AUTOSAR XML (schema 4-2-1)
package /ComponentTypes
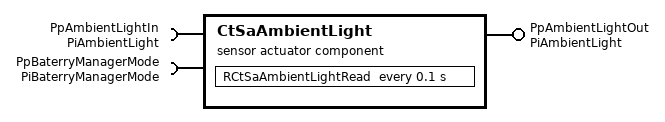
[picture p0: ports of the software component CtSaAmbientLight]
  sensor actuator sw component type CtSaAmbientLight
    provide port PpAmbientLightOut: nonqueued-sender-com-spec{data-element=DeAmbientLight, init-value=0}, provided-interface=PiAmbientLight
    require port PpAmbientLightIn: nonqueued-receiver-com-spec{data-element=DeAmbientLight, filter=data-filter-type=ALWAYS, init-value=0}, required-interface=PiAmbientLight
    require port PpBaterryManagerMode: mode-switch-receiver-com-spec{enhanced-mode-api=false, supports-asynchronous-mode-switch=false}, required-interface=PiBaterryManagerMode
    behavior CtSaAmbientLight_InternalBehavior
      timing event TMT_RCtSaAmbientLightRead: disabled-mode=PpBaterryManagerMode.Mode.BATTERY_LOW, start-on-event=RCtSaAmbientLightRead, period=0.1
      runnable RCtSaAmbientLightRead
        data-receive-point-by-arguments:
          access REC_PpAmbientLightIn_DeAmbientLight: accessed-variable=PpAmbientLightIn.DeAmbientLight
        data-send-points:
          access SEND_PpAmbientLightOut_DeAmbientLight: accessed-variable=PpAmbientLightOut.DeAmbientLight
  swc implementation CtSaAmbientLight_Implementation: behavior=CtSaAmbientLight_InternalBehavior
    code-descriptors:
      code Default: artifact-descriptors=autosar-engineering-object={short-label=Default, category=SWSRC}
